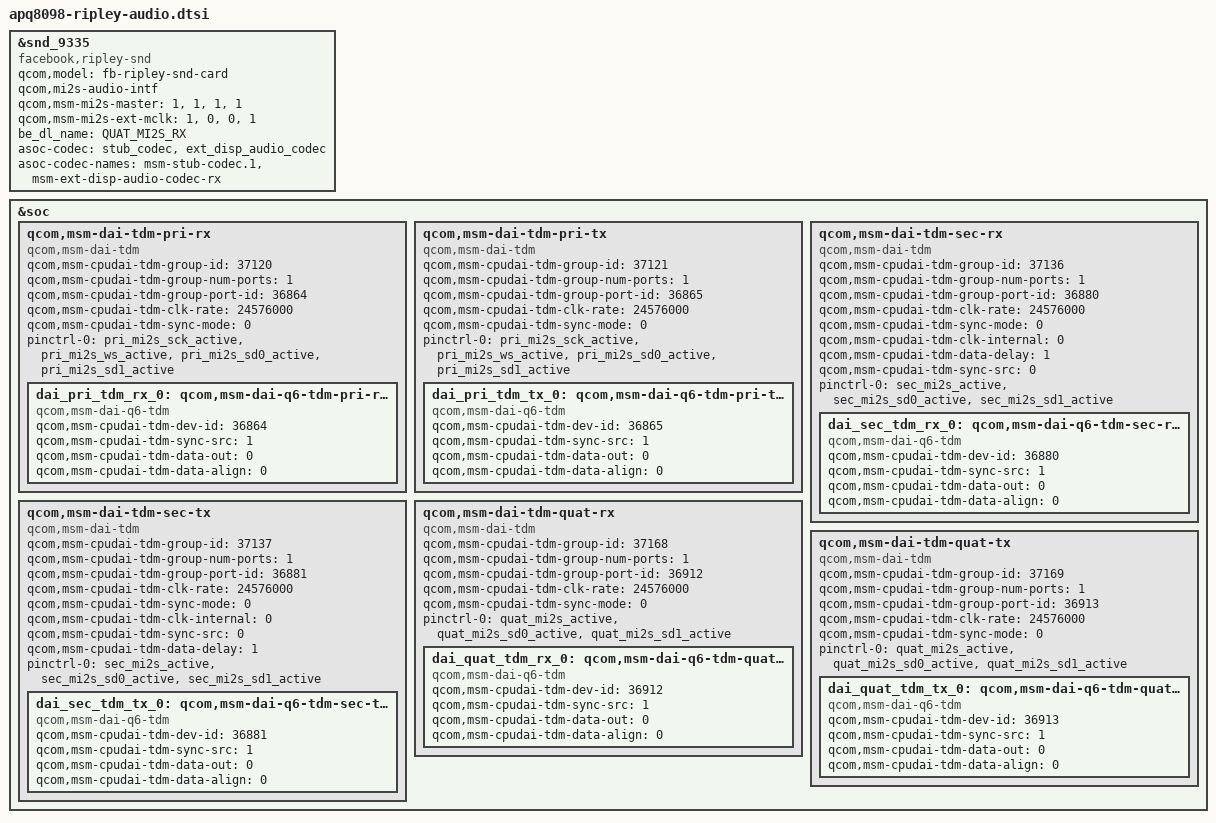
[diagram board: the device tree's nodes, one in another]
/* Copyright (c) 2018, Facebook Inc. All rights reserved.
 *
 * This program is free software; you can redistribute it and/or modify
 * it under the terms of the GNU General Public License version 2 and
 * only version 2 as published by the Free Software Foundation.
 *
 * This program is distributed in the hope that it will be useful,
 * but WITHOUT ANY WARRANTY; without even the implied warranty of
 * MERCHANTABILITY or FITNESS FOR A PARTICULAR PURPOSE.  See the
 * GNU General Public License for more details.
 */

/* Machine driver definition */
&snd_9335 {
	compatible = "facebook,ripley-snd";
	qcom,model = "fb-ripley-snd-card";

	/delete-property/ qcom,ext-disp-audio-rx;
	/delete-property/ qcom,auxpcm-audio-intf;
	/delete-property/ qcom,wsa-max-devs;
	/delete-property/ qcom,wsa-devs;
	/delete-property/ qcom,wsa-aux-dev-prefix;

	/delete-property/ qcom,us-euro-gpios;
	/delete-property/ qcom,hph-en0-gpio;
	/delete-property/ qcom,hph-en1-gpio;

	qcom,mi2s-audio-intf;
	qcom,msm-mi2s-master = <1>, <1>, <1>, <1>;
	qcom,msm-mi2s-ext-mclk = <1>, <0>, <0>, <1>;
	be_dl_name = "QUAT_MI2S_RX";

	asoc-codec = <&stub_codec>, <&ext_disp_audio_codec>;
	asoc-codec-names = "msm-stub-codec.1", "msm-ext-disp-audio-codec-rx";
};

&soc {
	qcom,msm-dai-tdm-pri-rx {
		compatible = "qcom,msm-dai-tdm";
		qcom,msm-cpudai-tdm-group-id = <37120>;
		qcom,msm-cpudai-tdm-group-num-ports = <1>;
		qcom,msm-cpudai-tdm-group-port-id = <36864>;
		qcom,msm-cpudai-tdm-clk-rate = <24576000>;
		qcom,msm-cpudai-tdm-sync-mode = <0>;

		pinctrl-names = "default";
		pinctrl-0 = <	&pri_mi2s_sck_active
				&pri_mi2s_ws_active
				&pri_mi2s_sd0_active
				&pri_mi2s_sd1_active>;
		dai_pri_tdm_rx_0: qcom,msm-dai-q6-tdm-pri-rx-0 {
			compatible = "qcom,msm-dai-q6-tdm";
			qcom,msm-cpudai-tdm-dev-id = <36864>;
			qcom,msm-cpudai-tdm-sync-src = <1>;
			qcom,msm-cpudai-tdm-data-out = <0>;
			qcom,msm-cpudai-tdm-data-align = <0>;
		};
	};

	qcom,msm-dai-tdm-pri-tx {
		compatible = "qcom,msm-dai-tdm";
		qcom,msm-cpudai-tdm-group-id = <37121>;
		qcom,msm-cpudai-tdm-group-num-ports = <1>;
		qcom,msm-cpudai-tdm-group-port-id = <36865>;
		qcom,msm-cpudai-tdm-clk-rate = <24576000>;
		qcom,msm-cpudai-tdm-sync-mode = <0>;

		pinctrl-names = "default";
		pinctrl-0 = <	&pri_mi2s_sck_active
				&pri_mi2s_ws_active
				&pri_mi2s_sd0_active
				&pri_mi2s_sd1_active>;

		dai_pri_tdm_tx_0: qcom,msm-dai-q6-tdm-pri-tx-0 {
			compatible = "qcom,msm-dai-q6-tdm";
			qcom,msm-cpudai-tdm-dev-id = <36865>;
			qcom,msm-cpudai-tdm-sync-src = <1>;
			qcom,msm-cpudai-tdm-data-out = <0>;
			qcom,msm-cpudai-tdm-data-align = <0>;
		};
	};

	qcom,msm-dai-tdm-sec-rx {
		compatible = "qcom,msm-dai-tdm";
		qcom,msm-cpudai-tdm-group-id = <37136>;
		qcom,msm-cpudai-tdm-group-num-ports = <1>;
		qcom,msm-cpudai-tdm-group-port-id = <36880>;
		qcom,msm-cpudai-tdm-clk-rate = <24576000>;
		qcom,msm-cpudai-tdm-sync-mode = <0>;
		qcom,msm-cpudai-tdm-clk-internal = <0>;
		qcom,msm-cpudai-tdm-data-delay = <1>;
		qcom,msm-cpudai-tdm-sync-src = <0>;
		pinctrl-names = "default";
		pinctrl-0 = <	&sec_mi2s_active
				&sec_mi2s_sd0_active
				&sec_mi2s_sd1_active>;
		dai_sec_tdm_rx_0: qcom,msm-dai-q6-tdm-sec-rx-0 {
			compatible = "qcom,msm-dai-q6-tdm";
			qcom,msm-cpudai-tdm-dev-id = <36880>;
			qcom,msm-cpudai-tdm-sync-src = <1>;
			qcom,msm-cpudai-tdm-data-out = <0>;
			qcom,msm-cpudai-tdm-data-align = <0>;
		};
	};

	qcom,msm-dai-tdm-sec-tx {
		compatible = "qcom,msm-dai-tdm";
		qcom,msm-cpudai-tdm-group-id = <37137>;
		qcom,msm-cpudai-tdm-group-num-ports = <1>;
		qcom,msm-cpudai-tdm-group-port-id = <36881>;
		qcom,msm-cpudai-tdm-clk-rate = <24576000>;
		qcom,msm-cpudai-tdm-sync-mode = <0>;
		qcom,msm-cpudai-tdm-clk-internal = <0>;
		qcom,msm-cpudai-tdm-sync-src = <0>;
		qcom,msm-cpudai-tdm-data-delay = <1>;
		pinctrl-names = "default";
		pinctrl-0 = <	&sec_mi2s_active
				&sec_mi2s_sd0_active
				&sec_mi2s_sd1_active>;

		dai_sec_tdm_tx_0: qcom,msm-dai-q6-tdm-sec-tx-0 {
			compatible = "qcom,msm-dai-q6-tdm";
			qcom,msm-cpudai-tdm-dev-id = <36881>;
			qcom,msm-cpudai-tdm-sync-src = <1>;
			qcom,msm-cpudai-tdm-data-out = <0>;
			qcom,msm-cpudai-tdm-data-align = <0>;
		};
	};

	qcom,msm-dai-tdm-quat-rx {
		compatible = "qcom,msm-dai-tdm";
		qcom,msm-cpudai-tdm-group-id = <37168>;
		qcom,msm-cpudai-tdm-group-num-ports = <1>;
		qcom,msm-cpudai-tdm-group-port-id = <36912>;
		qcom,msm-cpudai-tdm-clk-rate = <24576000>;
		qcom,msm-cpudai-tdm-sync-mode = <0>;

		pinctrl-names = "default";
		pinctrl-0 = <	&quat_mi2s_active
				&quat_mi2s_sd0_active
				&quat_mi2s_sd1_active>;

		dai_quat_tdm_rx_0: qcom,msm-dai-q6-tdm-quat-rx-0 {
			compatible = "qcom,msm-dai-q6-tdm";
			qcom,msm-cpudai-tdm-dev-id = <36912>;
			qcom,msm-cpudai-tdm-sync-src = <1>;
			qcom,msm-cpudai-tdm-data-out = <0>;
			qcom,msm-cpudai-tdm-data-align = <0>;
		};
	};

	qcom,msm-dai-tdm-quat-tx {
		compatible = "qcom,msm-dai-tdm";
		qcom,msm-cpudai-tdm-group-id = <37169>;
		qcom,msm-cpudai-tdm-group-num-ports = <1>;
		qcom,msm-cpudai-tdm-group-port-id = <36913>;
		qcom,msm-cpudai-tdm-clk-rate = <24576000>;
		qcom,msm-cpudai-tdm-sync-mode = <0>;

		pinctrl-names = "default";
		pinctrl-0 = <	&quat_mi2s_active
				&quat_mi2s_sd0_active
				&quat_mi2s_sd1_active>;

		dai_quat_tdm_tx_0: qcom,msm-dai-q6-tdm-quat-tx-0 {
			compatible = "qcom,msm-dai-q6-tdm";
			qcom,msm-cpudai-tdm-dev-id = <36913>;
			qcom,msm-cpudai-tdm-sync-src = <1>;
			qcom,msm-cpudai-tdm-data-out = <0>;
			qcom,msm-cpudai-tdm-data-align = <0>;
		};
	};
};

